VERSION ""

NS_ :

BS_:

BU_:

BO_ 3221225472 VECTOR__INDEPENDENT_SIG_MSG: 0 Vector__XXX
 SG_ PGN65304Res : 0|24@1- (1,0) [0|0] "" Vector__XXX
 SG_ Pressure : 0|32@1- (0.01,0) [0|0] "pa" Vector__XXX
 SG_ PGN65347Res : 0|16@1- (1,0) [0|0] "" Vector__XXX
 SG_ Temperature : 0|16@1- (0.01,0) [0|0] "бц" Vector__XXX

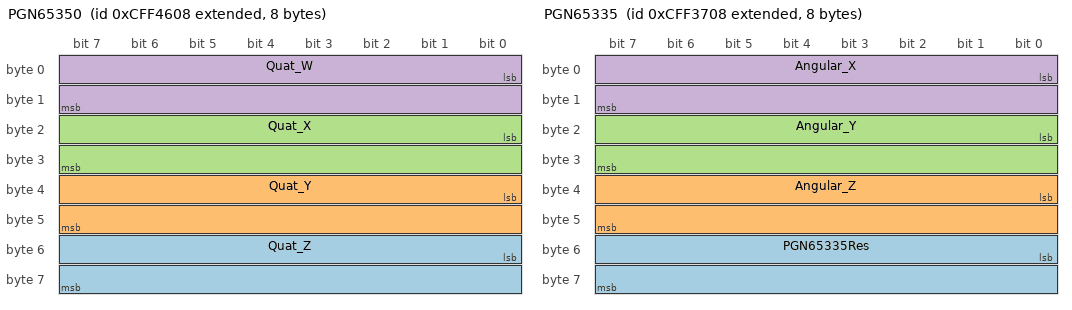
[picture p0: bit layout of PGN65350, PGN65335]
BO_ 2365539848 PGN65350: 8 Vector__XXX
 SG_ Quat_Z : 48|16@1- (0.0001,0) [0|0] "" Vector__XXX
 SG_ Quat_Y : 32|16@1- (0.0001,0) [0|0] "" Vector__XXX
 SG_ Quat_X : 16|16@1- (0.0001,0) [0|0] "" Vector__XXX
 SG_ Quat_W : 0|16@1- (0.0001,0) [-1|1] "" Vector__XXX

BO_ 2365538568 PGN65345: 8 Vector__XXX
 SG_ Yaw_2 : 32|32@1- (0.001,0) [0|0] "бу" Vector__XXX
 SG_ Yaw_1 : 0|32@1- (0.001,0) [0|0] "deg" Vector__XXX

BO_ 2365537544 PGN65341: 8 Vector__XXX
 SG_ Pitch : 32|32@1- (0.001,0) [0|0] "deg" Vector__XXX
 SG_ Roll : 0|32@1- (0.001,0) [0|0] "deg" Vector__XXX

BO_ 2365536008 PGN65335: 8 Vector__XXX
 SG_ PGN65335Res : 48|16@1- (1,0) [0|0] "" Vector__XXX
 SG_ Angular_Z : 32|16@1- (0.061035,0) [0|0] "deg/s" Vector__XXX
 SG_ Angular_Y : 16|16@1- (0.061035,0) [0|0] "deg/s" Vector__XXX
 SG_ Angular_X : 0|16@1- (0.061035,0) [0|0] "deg/s" Vector__XXX

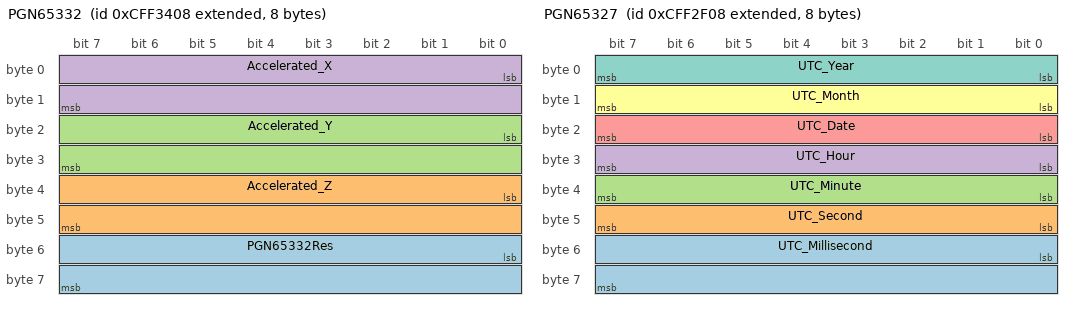
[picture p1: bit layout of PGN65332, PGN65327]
BO_ 2365535240 PGN65332: 8 Vector__XXX
 SG_ PGN65332Res : 48|16@1- (1,0) [0|0] "" Vector__XXX
 SG_ Accelerated_Z : 32|16@1- (0.00048828,0) [0|0] "G" Vector__XXX
 SG_ Accelerated_Y : 16|16@1- (0.00048828,0) [0|0] "G" Vector__XXX
 SG_ Accelerated_X : 0|16@1- (0.00048828,0) [0|0] "G" Vector__XXX

BO_ 2365533960 PGN65327: 8 Vector__XXX
 SG_ UTC_Millisecond : 48|16@1- (1,0) [0|0] "millisecond" Vector__XXX
 SG_ UTC_Second : 40|8@1- (1,0) [0|0] "second" Vector__XXX
 SG_ UTC_Minute : 32|8@1- (1,0) [0|0] "minute" Vector__XXX
 SG_ UTC_Hour : 24|8@1- (1,0) [0|0] "hour" Vector__XXX
 SG_ UTC_Date : 16|8@1- (1,0) [0|0] "date" Vector__XXX
 SG_ UTC_Month : 8|8@1- (1,0) [0|0] "month" Vector__XXX
 SG_ UTC_Year : 0|8@1- (1,0) [0|0] "year" Vector__XXX

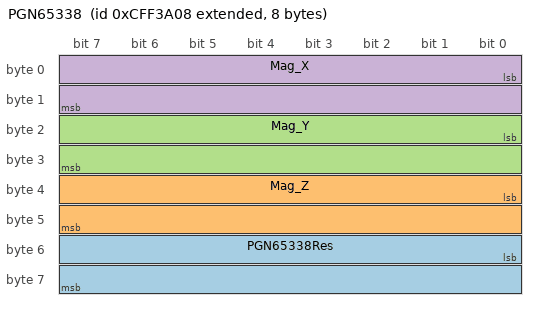
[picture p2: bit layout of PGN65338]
BO_ 2365536776 PGN65338: 8 Vector__XXX
 SG_ PGN65338Res : 48|16@1- (0.030517,0) [0|0] "uT" Vector__XXX
 SG_ Mag_Z : 32|16@1- (0.030517,0) [0|0] "uT" Vector__XXX
 SG_ Mag_Y : 16|16@1- (0.030517,0) [0|0] "uT" Vector__XXX
 SG_ Mag_X : 0|16@1- (0.030517,0) [0|0] "uT" Vector__XXX

BO_ 2365540872 PGN65354: 8 Vector__XXX
 SG_ Inc_Y : 32|32@1- (0.001,0) [0|0] "бу" Vector__XXX
 SG_ Inc_X : 0|32@1- (0.001,0) [0|0] "бу" Vector__XXX

CM_ BO_ 3221225472 "This is a message for not used signals, created by Vector CANdb++ DBC OLE DB Provider.";
BA_DEF_ BO_  "New_AttrDef_13" ENUM  "Cyclic","Enent";
BA_DEF_  "BusType" STRING ;
BA_DEF_DEF_  "New_AttrDef_13" "Cyclic";
BA_DEF_DEF_  "BusType" "CAN";
